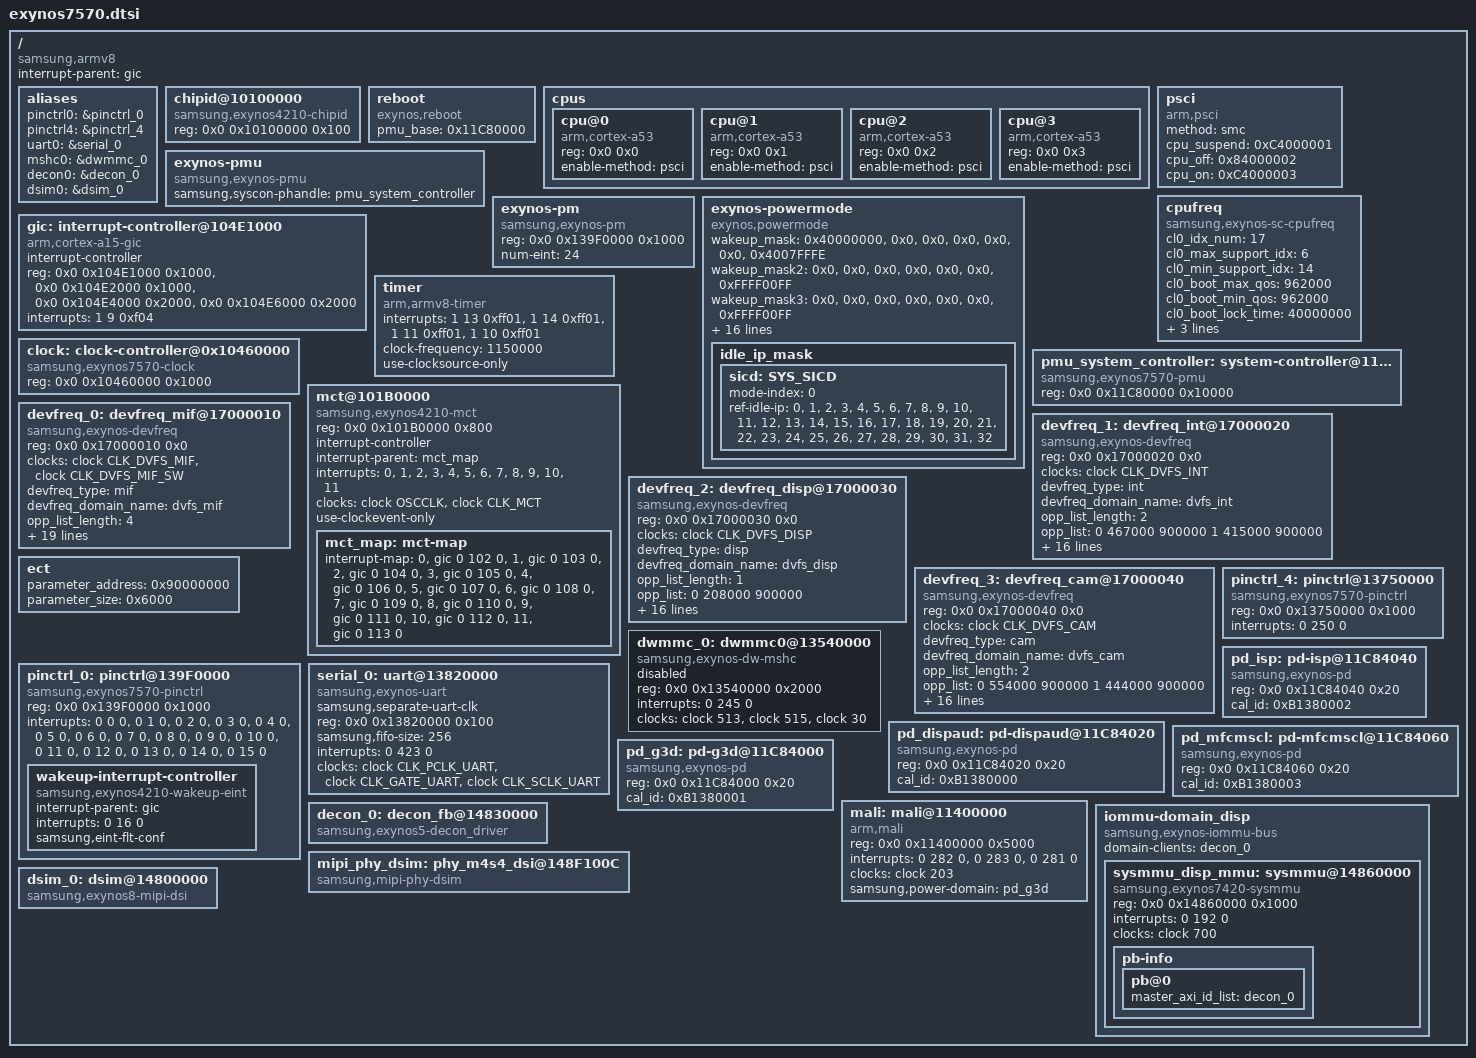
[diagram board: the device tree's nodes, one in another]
/*
 * SAMSUNG EXYNOS7570 SoC device tree source
 *
 * Copyright (c) 2015 Samsung Electronics Co., Ltd.
 *		http://www.samsung.com
 *
 * SAMSUNG EXYNOS7570 SoC device nodes are listed in this file.
 * EXYNOS7570 based board files can include this file and provide
 * values for board specfic bindings.
 *
 * This program is free software; you can redistribute it and/or modify
 * it under the terms of the GNU General Public License version 2 as
 * published by the Free Software Foundation.
 */

#include <dt-bindings/clock/exynos7570.h>
#include <dt-bindings/sysmmu/sysmmu.h>
/include/ "exynos7570-pinctrl.dtsi"

/ {
	compatible = "samsung,armv8", "samsung,exynos7570";
	interrupt-parent = <&gic>;
	#address-cells = <2>;
	#size-cells = <1>;

	aliases {
		pinctrl0 = &pinctrl_0;
		pinctrl4 = &pinctrl_4;
		uart0 = &serial_0;
		mshc0 = &dwmmc_0;
		decon0 = &decon_0;
		dsim0 = &dsim_0;
	};

	chipid@10100000 {
		compatible = "samsung,exynos4210-chipid";
		reg = <0x0 0x10100000 0x100>;
	};

	reboot {
		compatible = "exynos,reboot";
		pmu_base = <0x11C80000>;
	};

	cpus {
		#address-cells = <2>;
		#size-cells = <0>;

		cpu@0 {
			device_type = "cpu";
			compatible = "arm,cortex-a53", "arm,armv8";
			reg = <0x0 0x0>;
			enable-method = "psci";
		};
		cpu@1 {
			device_type = "cpu";
			compatible = "arm,cortex-a53", "arm,armv8";
			reg = <0x0 0x1>;
			enable-method = "psci";
		};
		cpu@2 {
			device_type = "cpu";
			compatible = "arm,cortex-a53", "arm,armv8";
			reg = <0x0 0x2>;
			enable-method = "psci";
		};
		cpu@3 {
			device_type = "cpu";
			compatible = "arm,cortex-a53", "arm,armv8";
			reg = <0x0 0x3>;
			enable-method = "psci";
		};
	};

	exynos-pmu {
		compatible = "samsung,exynos-pmu";
		samsung,syscon-phandle = <&pmu_system_controller>;
	};

	psci {
                compatible = "arm,psci";
                method = "smc";
                cpu_suspend = <0xC4000001>;
                cpu_off = <0x84000002>;
                cpu_on = <0xC4000003>;
        };

	cpufreq {
		compatible = "samsung,exynos-sc-cpufreq";

                cl0_idx_num = <17>;
                cl0_max_support_idx = <6>;
                cl0_min_support_idx = <14>;
                cl0_boot_max_qos = <962000>;
                cl0_boot_min_qos = <962000>;
                cl0_boot_lock_time = <40000000>;
                cl0_en_ema = <0>;
                cl0_regulator = "emul-null";

                cl0_dvfs_domain_name = "dvfs_cpucl0";
	};

	exynos-pm {
		compatible = "samsung,exynos-pm";
		reg = <0x0 0x139F0000 0x1000>;
		reg-names = "gpio_alive_base";
		num-eint = <24>;
	};

	exynos-powermode {
		compatible = "exynos,powermode";

		/*	        sicd		aftr		stop		lpd
		 *		lpa		dstop		sleep
		 */
		wakeup_mask =  <0x40000000>,	<0x0>,		<0x0>,		<0x0>,
			       <0x0>,		<0x0>,		<0x4007FFFE>;
		wakeup_mask2 = <0x0>,		<0x0>,		<0x0>,		<0x0>,
			       <0x0>,		<0x0>,		<0xFFFF00FF>;
		wakeup_mask3 = <0x0>,		<0x0>,		<0x0>,		<0x0>,
			       <0x0>,		<0x0>,		<0xFFFF00FF>;

		cpd_residency = <3000>;
		sicd_residency = <3000>;

		sicd_enabled = <0>;

		idle-ip = "136c0000.pwm",		/* idle ip index : 0 */
			  "10550000.adc",		/* idle ip index : 1 */

			  "10510000.hsi2c",		/* idle ip index : 2 */
			  "13950000.hsi2c",		/* idle ip index : 3 */
			  "13960000.hsi2c",		/* idle ip index : 4 */
			  "138a0000.hsi2c",		/* idle ip index : 5 */
			  "138b0000.hsi2c",		/* idle ip index : 6 */
			  "138c0000.hsi2c",		/* idle ip index : 7 */
			  "138f0000.hsi2c",		/* idle ip index : 8 */

			  "13870000.i2c",		/* idle ip index : 9 */
			  "13880000.i2c",		/* idle ip index : 10 */
			  "13890000.i2c",		/* idle ip index : 11 */
			  "13840000.i2c",		/* idle ip index : 12 */
			  "13830000.i2c",		/* idle ip index : 13 */
			  "138d0000.i2c",		/* idle ip index : 14 */
			  "138e0000.i2c",		/* idle ip index : 15 */
			  "13850000.i2c",		/* idle ip index : 16 */
			  "13860000.i2c",		/* idle ip index : 17 */

			  "13540000.dwmmc0",		/* idle ip index : 18 */
			  "13560000.dwmmc2",		/* idle ip index : 19 */

			  "13600000.usb",		/* idle ip index : 20 */

			  "100c0000.spi",		/* idle ip index : 21 */
			  "13900000.spi",		/* idle ip index : 22 */
			  "13910000.spi",		/* idle ip index : 23 */
			  "13920000.spi",		/* idle ip index : 24 */
			  "13930000.spi",		/* idle ip index : 25 */

			  "10500000.mailbox-cp",	/* idle ip index : 26 */
			  "10570000.mailbox-gnss",	/* idle ip index : 27 */

			  "14830000.decon_fb",		/* idle ip index : 28 */
			  "pd-g3d",			/* idle ip index : 29 */
			  "pd-isp",			/* idle ip index : 30 */
			  "pd-mfcmscl",			/* idle ip index : 31 */
			  "148f0000.lpass";             /* idle ip index : 32 */
		idle_ip_mask {
			sicd: SYS_SICD {
				mode-index = <0>;
				ref-idle-ip = <0>,  <1>,  <2>,  <3>,  <4>,  <5>,  <6>,  <7>,  <8>,  <9>,
					     <10>, <11>, <12>, <13>, <14>, <15>, <16>, <17>, <18>, <19>,
					     <20>, <21>, <22>, <23>, <24>, <25>, <26>, <27>, <28>, <29>,
					     <30>, <31>, <32>;
			};
		};
	};

	gic:interrupt-controller@104E1000 {
		compatible = "arm,cortex-a15-gic", "arm,cortex-a9-gic";
		#interrupt-cells = <3>;
		#address-cells = <0>;
		interrupt-controller;
		reg =	<0x0 0x104E1000 0x1000>,
			<0x0 0x104E2000 0x1000>,
			<0x0 0x104E4000 0x2000>,
			<0x0 0x104E6000 0x2000>;
		interrupts = <1 9 0xf04>;
	};

	timer {
	        compatible = "arm,armv8-timer";
	        interrupts = <1 13 0xff01>,
	                     <1 14 0xff01>,
	                     <1 11 0xff01>,
	                     <1 10 0xff01>;
	        clock-frequency = <1150000>;
		use-clocksource-only;
	};

	clock: clock-controller@0x10460000 {
		compatible = "samsung,exynos7570-clock";
		reg = <0x0 0x10460000 0x1000>;
		#clock-cells = <1>;
	};

	pmu_system_controller: system-controller@11C80000 {
		compatible = "samsung,exynos7570-pmu", "syscon";
		reg = <0x0 0x11C80000 0x10000>;
	};

	mct@101B0000 {
		compatible = "samsung,exynos4210-mct";
		reg = <0x0 0x101B0000 0x800>;
		interrupt-controller;
		#interrupt-cells = <1>;
		interrupt-parent = <&mct_map>;
		interrupts =	<0>, <1>, <2>, <3>,
				<4>, <5>, <6>, <7>,
				<8>, <9>, <10>, <11>;
		clocks = <&clock OSCCLK>, <&clock CLK_MCT>;
		clock-names = "fin_pll", "mct";
		use-clockevent-only;

		mct_map: mct-map {
			#interrupt-cells = <1>;
			#address-cells = <0>;
			#size-cells = <0>;
			interrupt-map = <0 &gic 0 102 0>,
					<1 &gic 0 103 0>,
					<2 &gic 0 104 0>,
					<3 &gic 0 105 0>,
					<4 &gic 0 106 0>,
					<5 &gic 0 107 0>,
					<6 &gic 0 108 0>,
					<7 &gic 0 109 0>,
					<8 &gic 0 110 0>,
					<9 &gic 0 111 0>,
					<10 &gic 0 112 0>,
					<11 &gic 0 113 0>;
		};
	};

	devfreq_0: devfreq_mif@17000010 {
		compatible = "samsung,exynos-devfreq";
		reg = <0x0 0x17000010 0x0>;
		clocks = <&clock CLK_DVFS_MIF>, <&clock CLK_DVFS_MIF_SW>;
		clock-names = "dvfs_mif", "dvfs_mif_sw";
		devfreq_type = "mif";
		devfreq_domain_name = "dvfs_mif";
		opp_list_length = <4>;
		opp_list = < 0 830000 900000
			     1 700000 900000
			     2 666000 900000
			     3 415000 900000>;

		/* initial_freq, default_qos, suspend_freq, cal_qos_max, min_freq, max_freq */
		freq_info = <830000 415000 415000 830000 415000 830000>;

		/* PM QoS */
		boot_qos_timeout = <40>;

		use_get_dev = "false";
		polling_ms = <0>;

		/* governor data */
		gov_name = "simple_exynos";
		urgent_thres = <80>;
		upthreshold = <70>;
		downthreshold = <60>;
		idlethreshold = <50>;

		/* regulator */
		use_reg = "true";
		use_reg_dummy = "false";
		reg_name = "BUCK2";
		/* cold, cold_limit, min_cold, max_uV */
		volt_info = <37500 1250000 0 1300000>;

		use_tmu = "false";
		use_cl_dvfs = "false";
		use_sw_clk = "true";
	};

	devfreq_1: devfreq_int@17000020 {
		compatible = "samsung,exynos-devfreq";
		reg = <0x0 0x17000020 0x0>;
		clocks = <&clock CLK_DVFS_INT>;
		clock-names = "dvfs_int";
		devfreq_type = "int";
		devfreq_domain_name = "dvfs_int";
		opp_list_length = <2>;
		/* idx freq volt */
		opp_list = <0 467000 900000
			    1 415000 900000>;

		/* <initial_freq, default_qos, suspend_freq, cal_qos_max, min, max> */
		freq_info = <467000 415000 415000 467000 415000 467000>;

		/* PM QoS */
		boot_qos_timeout = <40>;

		/* default_dev_profile */
		use_get_dev = "false";
		polling_ms = <0>;

		/* governor data */
		gov_name = "simple_ondemand";
		upthreshold = <95>;
		downdifferential = <5>;
		multi_weight = <100>;

		/* regulator */
		use_reg = "true";
		use_reg_dummy = "false";
		reg_name = "BUCK2";
		/* <cold, cold_limit, min_cold, max_uV> */
		volt_info = <37500 1250000 0 1300000>;

		use_tmu = "false";
		use_cl_dvfs = "false";
		use_sw_clk = "false";
	};

	devfreq_2: devfreq_disp@17000030 {
		compatible = "samsung,exynos-devfreq";
		reg = <0x0 0x17000030 0x0>;
		clocks = <&clock CLK_DVFS_DISP>;
		clock-names = "dvfs_disp";
		devfreq_type = "disp";
		devfreq_domain_name = "dvfs_disp";
		opp_list_length = <1>;
		/* idx freq volt */
		opp_list = <0 208000 900000>;

		/* <initial_freq, default_qos, suspend_freq, cal_qos_max, min, max> */
		freq_info = <208000 208000 208000 208000 208000 208000>;

		/* PM QoS */
		boot_qos_timeout = <40>;

		/* default dev profile */
		use_get_dev = "false";
		polling_ms = <0>;

		/* governor data */
		gov_name = "simple_ondemand";
		upthreshold = <95>;
		downdifferential = <5>;
		multi_weight = <100>;

		/* regulator */
		use_reg = "true";
		use_reg_dummy = "false";
		reg_name = "BUCK2";
		/* cold, cold_limit, min_cold, max_uV */
		volt_info = <37500 1250000 0 1300000>;

		use_tmu = "false";
		use_cl_dvfs = "false";
		use_sw_clk = "false";
	};

	devfreq_3: devfreq_cam@17000040 {
		compatible = "samsung,exynos-devfreq";
		reg = <0x0 0x17000040 0x0>;
		clocks = <&clock CLK_DVFS_CAM>;
		clock-names = "dvfs_cam";
		devfreq_type = "cam";
		devfreq_domain_name = "dvfs_cam";
		opp_list_length = <2>;
		opp_list = <0 554000 900000
			    1 444000 900000>;

		/* <initial, default_qos, suspend_freq, cal_qos_max, min, max> */
		freq_info = <554000 444000 554000 554000 444000 554000>;

		/* PM QoS */
		boot_qos_timeout = <0>;

		/* default dev profile */
		use_get_dev = "false";
		polling_ms = <0>;

		/* governor data */
		gov_name = "simple_ondemand";
		upthreshold = <95>;
		downdifferential = <5>;
		multi_weight = <100>;

		/* regulator */
		use_reg = "true";
		use_reg_dummy = "true";
		reg_name = "BUCK2";
		/* cold, cold_limit, min_cold, max_uV */
		volt_info = <37500 1250000 0 1300000>;

		use_tmu = "false";
		use_cl_dvfs = "false";
		use_sw_clk = "false";
	};

	ect {
		parameter_address = <0x90000000>;
		parameter_size = <0x6000>;
	};

	pinctrl_0: pinctrl@139F0000 {
		compatible = "samsung,exynos7570-pinctrl";
		reg = <0x0 0x139F0000 0x1000>;
		interrupts = <0 0 0>, <0 1 0>, <0 2 0>, <0 3 0>,
				<0 4 0>, <0 5 0>, <0 6 0>, <0 7 0>,
				<0 8 0>, <0 9 0>, <0 10 0>, <0 11 0>,
				<0 12 0>, <0 13 0>, <0 14 0>, <0 15 0>;
		wakeup-interrupt-controller {
			compatible = "samsung,exynos4210-wakeup-eint";
			interrupt-parent = <&gic>;
			interrupts = <0 16 0>;
			samsung,eint-flt-conf;
		};
	};

	/* FSYS0 */
	pinctrl_4: pinctrl@13750000 {
		compatible = "samsung,exynos7570-pinctrl";
		reg = <0x0 0x13750000 0x1000>;
		interrupts = <0 250 0>;
	};

	serial_0: uart@13820000 {
		compatible = "samsung,exynos-uart";
		samsung,separate-uart-clk;
		reg = <0x0 0x13820000 0x100>;
		samsung,fifo-size = <256>;
		interrupts = <0 423 0>;
		pinctrl-names = "default";
		clocks = <&clock CLK_PCLK_UART>, <&clock CLK_GATE_UART>, <&clock CLK_SCLK_UART>;
		clock-names = "gate_pclk0", "gate_uart0", "clk_uart0";
		status = "okay";
	};

	dwmmc_0: dwmmc0@13540000 {
		compatible = "samsung,exynos-dw-mshc";
		reg = <0x0 0x13540000 0x2000>;
		interrupts = <0 245 0>;
		#address-cells = <1>;
		#size-cells = <0>;
		clocks = <&clock 513>, <&clock 515>, <&clock 30>;
		clock-names = "biu", "ciu", "ciu_gate";
		status = "disabled";
	 };

	pd_dispaud: pd-dispaud@11C84020 {
		compatible = "samsung,exynos-pd";
		reg = <0x0 0x11C84020 0x20>;
		cal_id = <0xB1380000>;
	};

	pd_isp: pd-isp@11C84040 {
		compatible = "samsung,exynos-pd";
		reg = <0x0 0x11C84040 0x20>;
		cal_id = <0xB1380002>;
	};

	pd_mfcmscl: pd-mfcmscl@11C84060 {
		compatible = "samsung,exynos-pd";
		reg = <0x0 0x11C84060 0x20>;
		cal_id = <0xB1380003>;
	};

	pd_g3d: pd-g3d@11C84000 {
		compatible = "samsung,exynos-pd";
		reg = <0x0 0x11C84000 0x20>;
		cal_id = <0xB1380001>;
	};

	mali: mali@11400000 {
		compatible = "arm,mali";
		reg = <0x0 0x11400000 0x5000>;
		interrupts = <0 282 0>, <0 283 0>, <0 281 0>;
		interrupt-names = "JOB", "MMU", "GPU";
		clocks = <&clock 203>;
		clock-names = "vclk_g3d";
		samsung,power-domain = <&pd_g3d>;
	};

	decon_0: decon_fb@14830000 {
		compatible = "samsung,exynos5-decon_driver";
		#pb-id-cells = <0>;
	};

	iommu-domain_disp {
		compatible = "samsung,exynos-iommu-bus";
		#address-cells = <2>;
		#size-cells = <1>;
		ranges;

		domain-clients = <&decon_0>;

		sysmmu_disp_mmu: sysmmu@14860000 {
			compatible = "samsung,exynos7420-sysmmu";
			reg = <0x0 0x14860000 0x1000>;
			interrupts = <0 192 0>;
			clocks = <&clock 700>;
			clock-names = "aclk";
			pb-info {
				pb@0 {
					master_axi_id_list = <&decon_0>;
				};
			};
		};
	};

	mipi_phy_dsim: phy_m4s4_dsi@148F100C {
		compatible = "samsung,mipi-phy-dsim";
	};

	dsim_0: dsim@14800000 {
		compatible = "samsung,exynos8-mipi-dsi";
	};

	decon_0: decon_fb@14830000 {
		compatible = "samsung,exynos5-decon_driver";
	};

};
